# SWM166 register map
File version: 1.0
CPU: CM0 r1p0, little endian, 2 interrupt priority bits
Registers are 32-bit, read-write, no defined reset value unless marked. A register's access mark holds for its fields unless they carry their own. Offsets are from the block's base; [hi:lo] are bit positions; lines under a group give offsets from that group; {n}, {i} and the like mark numbered series; 'fields as' and 'values as' point back to an identical list.

## CAN0 — Registers group
Base 0x400A8000
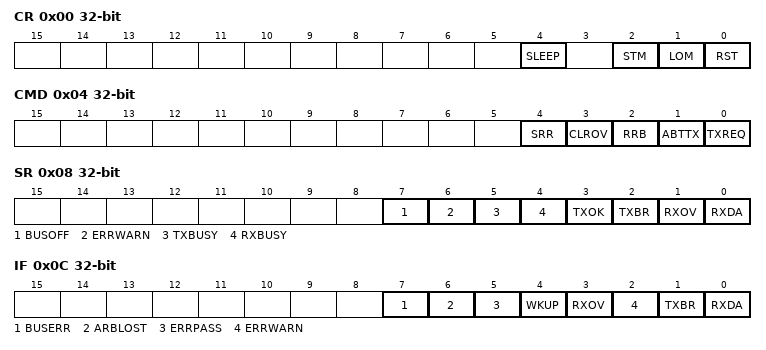
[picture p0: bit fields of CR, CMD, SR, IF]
0x00 CR
  [4] SLEEP, [2] STM, [1] LOM, [0] RST
0x04 CMD wo
  [4] SRR, [3] CLROV, [2] RRB, [1] ABTTX, [0] TXREQ
0x08 SR ro
  [7] BUSOFF, [6] ERRWARN, [5] TXBUSY, [4] RXBUSY, [3] TXOK, [2] TXBR, [1] RXOV, [0] RXDA
0x0C IF
  [7] BUSERR, [6] ARBLOST, [5] ERRPASS, [4] WKUP, [3] RXOV, [2] ERRWARN, [1] TXBR, [0] RXDA
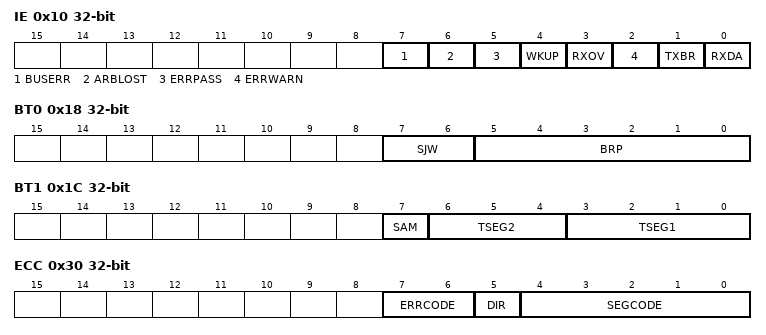
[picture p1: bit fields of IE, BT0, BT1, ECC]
0x10 IE
  fields as IF
0x14 BT2
  [3:0] BRP
0x18 BT0
  [7:6] SJW, [5:0] BRP
0x1C BT1
  [7] SAM, [6:4] TSEG2, [3:0] TSEG1
0x24 AFM
0x28 AFE
0x2C ALC ro
0x30 ECC ro
  [7:6] ERRCODE, [5] DIR, [4:0] SEGCODE
0x34 EWLIM
0x38 RXERR
0x3C TXERR
0x40 FRAME group — register cluster
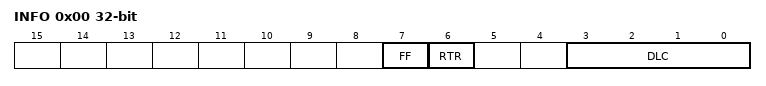
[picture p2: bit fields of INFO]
  0x00 INFO
    [7] FF, [6] RTR, [3:0] DLC
  {0x4+4j} DATA[{j}] (j=0..11)
0x74 RMCNT ro
{0x300+4i} ACR[{i}] (i=0..15)
{0x380+4i} AMR[{i}] (i=0..15)

## ADC0 — Registers group
Base 0x40049000
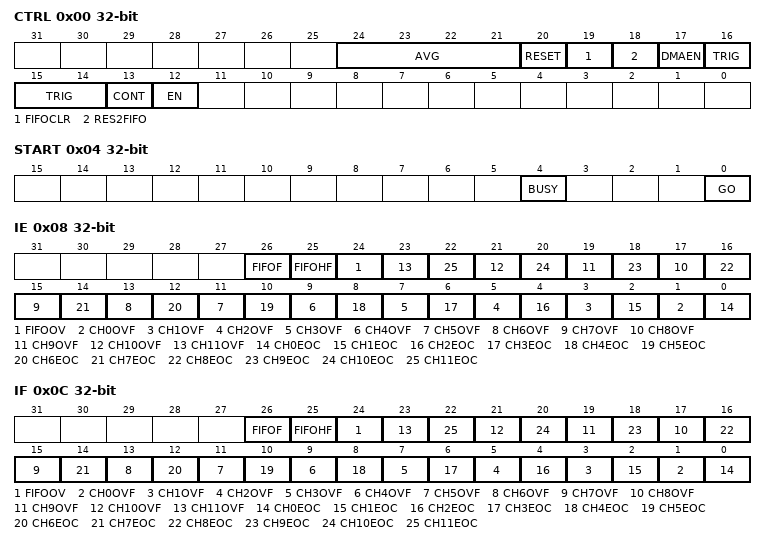
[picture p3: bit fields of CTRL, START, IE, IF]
0x00 CTRL
  [24:21] AVG, [20] RESET, [19] FIFOCLR, [18] RES2FIFO, [17] DMAEN, [16:14] TRIG, [13] CONT, [12] EN
0x04 START
  [4] BUSY, [0] GO
0x08 IE
  [26] FIFOF, [25] FIFOHF, [24] FIFOOV, [2n+1] CH{n}OVF (n=0..11), [2n] CH{n}EOC (n=0..11)
0x0C IF
  fields as IE
{0x10+0x10*i} CH{i} group (i=0..11) — register cluster
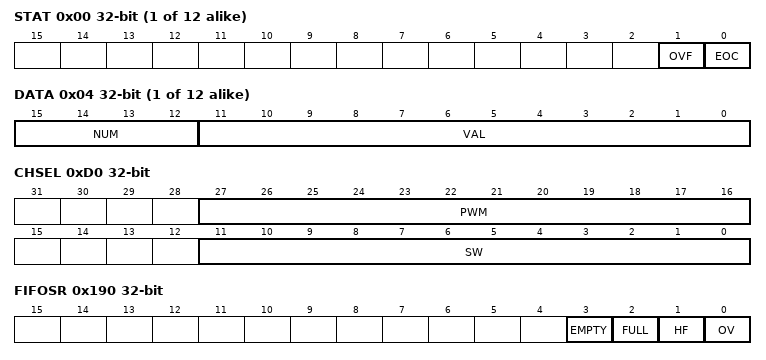
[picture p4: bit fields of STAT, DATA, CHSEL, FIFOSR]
  0x00 STAT
    [1] OVF, [0] EOC
  0x04 DATA
    [15:12] NUM, [11:0] VAL
0xD0 CHSEL
  [27:16] PWM, [11:0] SW
0x190 FIFOSR
  [3] EMPTY, [2] FULL, [1] HF, [0] OV
0x194 FIFODR
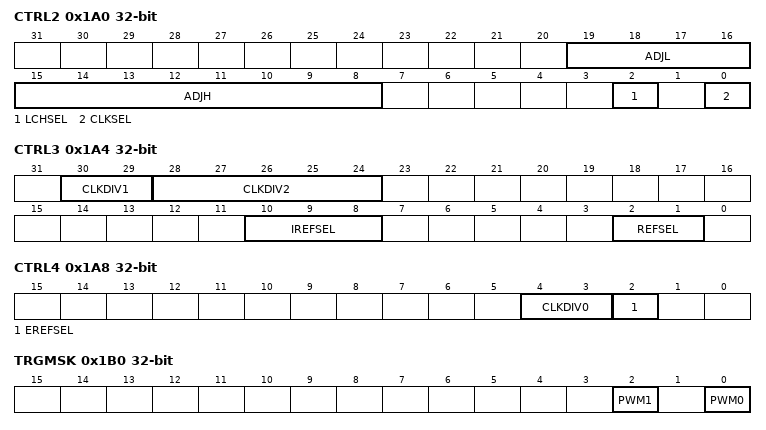
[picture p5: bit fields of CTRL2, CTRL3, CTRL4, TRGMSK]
0x1A0 CTRL2
  [19:16] ADJL, [15:8] ADJH, [2] LCHSEL, [0] CLKSEL
0x1A4 CTRL3
  [30:29] CLKDIV1, [28:24] CLKDIV2, [10:8] IREFSEL, [2:1] REFSEL
0x1A8 CTRL4
  [4:3] CLKDIV0, [2] EREFSEL
0x1B0 TRGMSK
  [2] PWM1, [0] PWM0
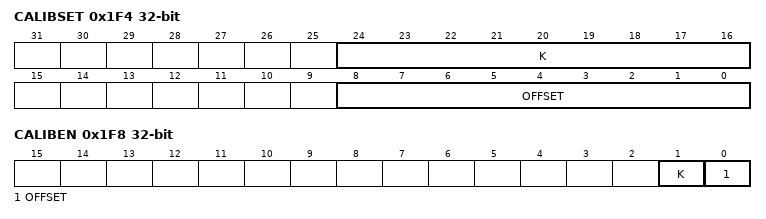
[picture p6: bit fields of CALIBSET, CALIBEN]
0x1F4 CALIBSET
  [24:16] K, [8:0] OFFSET
0x1F8 CALIBEN
  [1] K, [0] OFFSET

## PWM0 — Registers group
Base 0x40046000
Same registers: PWM1 0x40046080
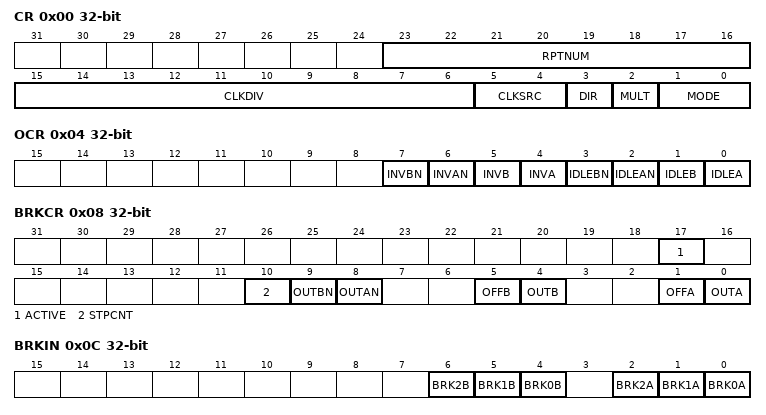
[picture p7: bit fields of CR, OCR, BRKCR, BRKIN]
0x00 CR
  [23:16] RPTNUM, [15:6] CLKDIV, [5:4] CLKSRC, [3] DIR, [2] MULT, [1:0] MODE
0x04 OCR
  [7] INVBN, [6] INVAN, [5] INVB, [4] INVA, [3] IDLEBN, [2] IDLEAN, [1] IDLEB, [0] IDLEA
0x08 BRKCR
  [17] ACTIVE, [10] STPCNT, [9] OUTBN, [8] OUTAN, [5] OFFB, [4] OUTB, [1] OFFA, [0] OUTA
0x0C BRKIN
  [6] BRK2B, [5] BRK1B, [4] BRK0B, [2] BRK2A, [1] BRK1A, [0] BRK0A
0x20 PERIOD
0x24 CMPA
0x28 CMPB
0x2C DZA
0x30 DZB
0x34 CMPA2
0x38 CMPB2
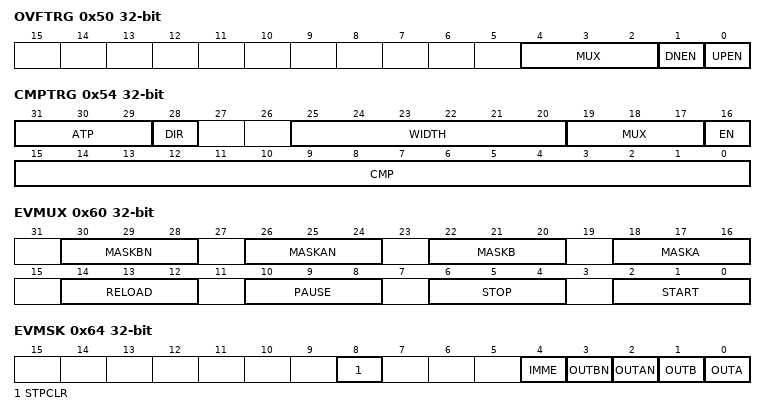
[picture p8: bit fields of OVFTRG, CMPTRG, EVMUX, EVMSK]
0x50 OVFTRG
  [4:2] MUX, [1] DNEN, [0] UPEN
0x54 CMPTRG
  [31:29] ATP, [28] DIR, [25:20] WIDTH, [19:17] MUX, [16] EN, [15:0] CMP
0x58 CMPTRG2
  [2:0] INTV
0x60 EVMUX
  [30:28] MASKBN, [26:24] MASKAN, [22:20] MASKB, [18:16] MASKA, [14:12] RELOAD, [10:8] PAUSE, [6:4] STOP, [2:0] START
0x64 EVMSK
  [8] STPCLR, [4] IMME, [3] OUTBN, [2] OUTAN, [1] OUTB, [0] OUTA
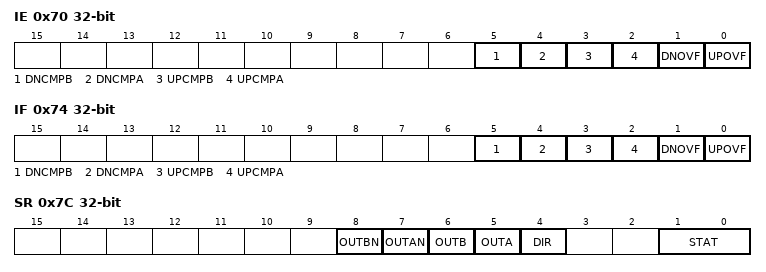
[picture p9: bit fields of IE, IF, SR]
0x70 IE
  [5] DNCMPB, [4] DNCMPA, [3] UPCMPB, [2] UPCMPA, [1] DNOVF, [0] UPOVF
0x74 IF
  [5] DNCMPB, [4] DNCMPA, [3] UPCMPB, [2] UPCMPA, [1] DNOVF, [0] UPOVF
0x78 VALUE
0x7C SR
  [8] OUTBN, [7] OUTAN, [6] OUTB, [5] OUTA, [4] DIR, [1:0] STAT

## PWMG — Registers group
Base 0x40046400
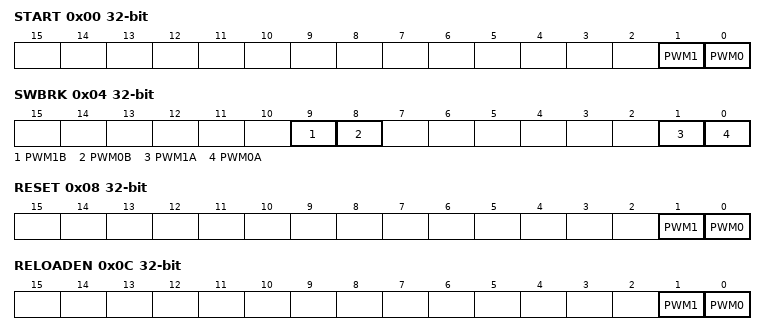
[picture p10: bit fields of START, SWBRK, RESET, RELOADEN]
0x00 START
  [1] PWM1, [0] PWM0
0x04 SWBRK
  [9] PWM1B, [8] PWM0B, [1] PWM1A, [0] PWM0A
0x08 RESET
  [1] PWM1, [0] PWM0
0x0C RELOADEN
  [1] PWM1, [0] PWM0
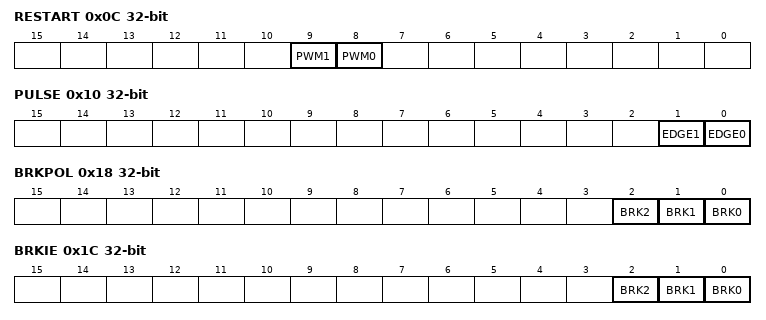
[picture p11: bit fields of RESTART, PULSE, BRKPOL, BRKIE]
0x0C RESTART (alternate view of RELOADEN)
  [9] PWM1, [8] PWM0
0x10 PULSE
  [1] EDGE1, [0] EDGE0
0x14 FILTER
0x18 BRKPOL
  [2] BRK2, [1] BRK1, [0] BRK0
0x1C BRKIE
  [2] BRK2, [1] BRK1, [0] BRK0
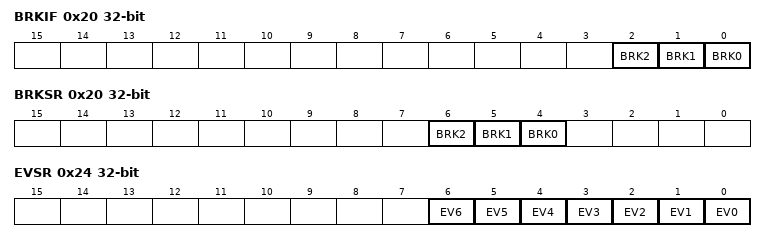
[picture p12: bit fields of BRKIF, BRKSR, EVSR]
0x20 BRKIF
  [2] BRK2, [1] BRK1, [0] BRK0
0x20 BRKSR (alternate view of BRKIF)
  [6] BRK2, [5] BRK1, [4] BRK0
0x24 EVSR
  [n] EV{n} (n=0..6)

## CORDIC — Registers group
Base 0x40003000
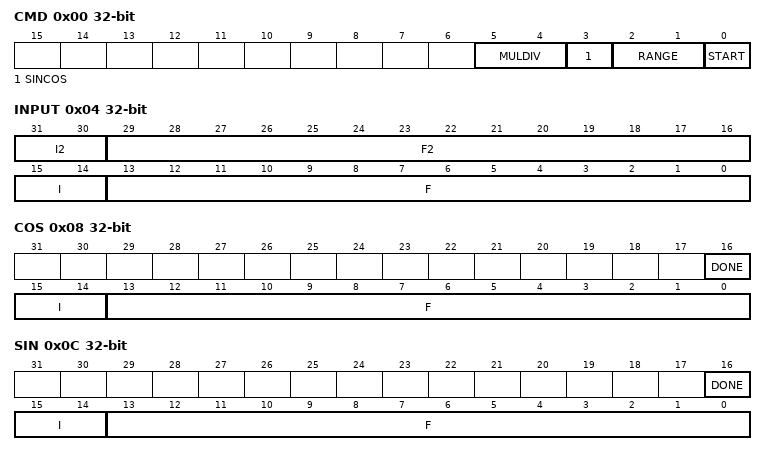
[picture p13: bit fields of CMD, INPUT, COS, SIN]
0x00 CMD
  [5:4] MULDIV, [3] SINCOS, [2:1] RANGE, [0] START
0x04 INPUT
  [31:30] I2, [29:16] F2, [15:14] I, [13:0] F
0x08 COS
  [16] DONE, [15:14] I, [13:0] F
0x0C SIN
  [16] DONE, [15:14] I, [13:0] F
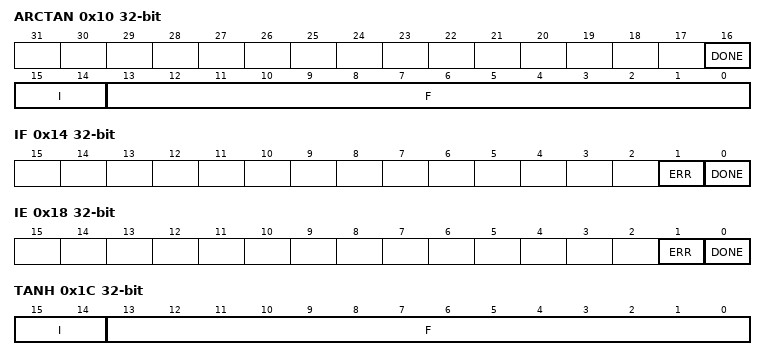
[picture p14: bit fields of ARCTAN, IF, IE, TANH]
0x10 ARCTAN
  [16] DONE, [15:14] I, [13:0] F
0x14 IF
  [1] ERR, [0] DONE
0x18 IE
  [1] ERR, [0] DONE
0x1C TANH
  [15:14] I, [13:0] F

## DIV — Registers group
Base 0x40003800
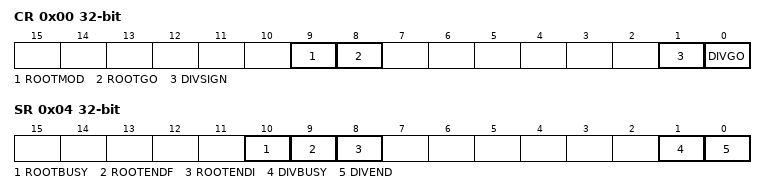
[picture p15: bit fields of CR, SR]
0x00 CR
  [9] ROOTMOD, [8] ROOTGO, [1] DIVSIGN, [0] DIVGO
0x04 SR
  [10] ROOTBUSY, [9] ROOTENDF, [8] ROOTENDI, [1] DIVBUSY, [0] DIVEND
0x08 IE
0x10 DIVIDEND
0x14 DIVISOR
0x18 QUO
0x1C REMAIN
0x20 RADICAND
0x24 ROOT

## DMA — Registers group
Base 0x40000800
0x00 EN
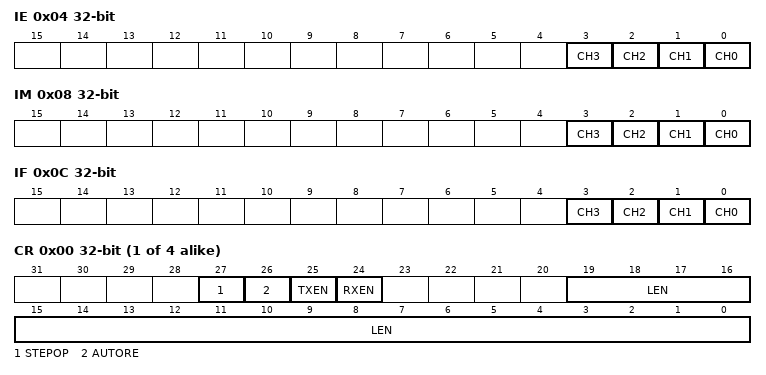
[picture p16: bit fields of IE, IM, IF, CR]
0x04 IE
  [n] CH{n} (n=0..3)
0x08 IM
  [n] CH{n} (n=0..3)
0x0C IF
  [n] CH{n} (n=0..3)
0x10 DSTSGIE
0x14 DSTSGIM
0x18 DSTSGIF
0x1C SRCSGIE
0x20 SRCSGIM
0x24 SRCSGIF
0x3C PRI
{0x40+0x40*i} CH{i} group (i=0..3) — register cluster
  0x00 CR
    [27] STEPOP, [26] AUTORE, [25] TXEN, [24] RXEN, [19:0] LEN
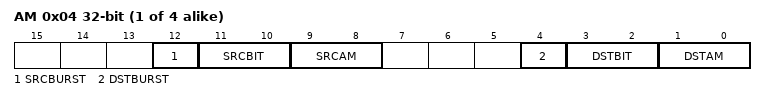
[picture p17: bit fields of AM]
  0x04 AM
    [12] SRCBURST, [11:10] SRCBIT, [9:8] SRCAM, [4] DSTBURST, [3:2] DSTBIT, [1:0] DSTAM
  0x08 DST
  {0x8+4j} DSTSGADDR{j} (j=1..3)
  0x18 MUX
    [19] EXTHSEN, [18:16] EXTHSSIG, [10] SRCHSEN, [9:8] SRCHSSIG, [2] DSTHSEN, [1:0] DSTHSSIG
  0x1C SRC
  {0x1C+4j} SRCSGADDR{j} (j=1..3)
  0x2C DSTSR ro
    [31] ERR, [19:0] LEN
  0x30 SRCSR ro
    [31] ERR, [19:0] LEN

## FMC — Registers group
Base 0x4004A000
0x00 DATA
0x04 ADDR
0x08 ERASE
  [31:24] REQ, [15:0] ADDR
0x0C CACHE
  [18] CCLR, [17] CPEN, [16] CEN, [0] PROGEN
0x10 CFG0
0x14 CFG1
0x18 STAT
  [31] IDLE, [4] FIFOFULL, [3] FIFOEMPTY, [2] READBUSY, [1] PROGBUSY, [0] ERASEBUSY
0x28 REMAP
  [5:1] OFFSET, [0] ON

## WDT — Registers group
Base 0x400A0800
0x00 RSTVAL
0x04 INTVAL
0x08 CR
  [11:8] CLKDIV, [3] WINEN, [2] INTEN, [1] RSTEN, [0] EN
0x0C IF
0x10 FEED

## QEI — Registers group
Base 0x4004D800
0x00 CR
  [10] PAUSE, [9] INDEX, [7] MODE, [6] RSTSRC, [5] X2X4, [4] ABSWAP, [0] ENA
0x04 POSCNT
0x08 MAXCNT
0x20 IE
  [3] ERROR, [2] CNTOV, [1] MATCH, [0] INDEX
0x24 IM
  [3] ERROR, [2] CNTOV, [1] MATCH, [0] INDEX
0x28 IC wo
  [3] ERROR, [2] CNTOV, [1] MATCH, [0] INDEX
0x2C IF ro
  [3] ERROR, [2] CNTOV, [1] MATCH, [0] INDEX
0x30 IFOV
  [3] ERROR, [2] CNTOV, [1] MATCH, [0] INDEX
